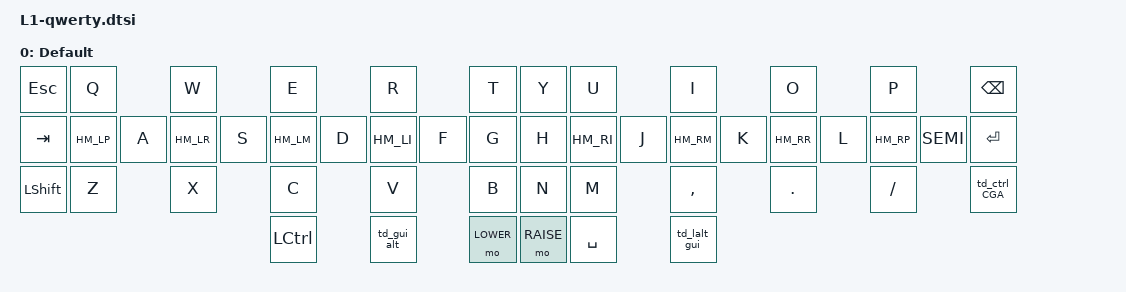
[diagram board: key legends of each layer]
/**
 *
 */

/ {
  keymap {
    compatible = "zmk,keymap";

	default_layer {
		label = "Default";
		bindings = <
// ╭───────────────┬───────────────┬───────────────┬───────────────┬───────────────┬───────────────╮   ╭───────────────┬───────────────┬───────────────┬───────────────┬───────────────┬───────────────╮
//  0               1               2               3               4               5                   6               7               8               9               10              11
    &kp ESC         &kp Q           &kp W           &kp E           &kp R           &kp T               &kp Y           &kp U           &kp I           &kp O           &kp P         	&kp BSPC
// ├───────────────├───────────────┼───────────────┼───────────────┼───────────────┼───────────────┤   ├───────────────├───────────────┼───────────────┼───────────────┼───────────────┼───────────────┤
//  12              13              14              15              16              17                  18              19              20              21              22              23
    &kp TAB			HM_LP A      	HM_LR S       	HM_LM D      	HM_LI F      	&kp G               &kp H           HM_RI J     	HM_RM K   		HM_RR L      	HM_RP SEMI		&kp ENTER
// ├───────────────├───────────────┼───────────────┼───────────────┼───────────────┼───────────────┤   ├───────────────├───────────────┼───────────────┼───────────────┼───────────────┼───────────────┤
//  24              25              26              27              28              29                  30              31              32              33              34              35
    &kp LSHFT 		&kp Z     		&kp X      		&kp C      		&kp V       	&kp B               &kp N           &kp M       	&kp COMMA  		&kp DOT   		&kp FSLH  		&td_ctrl_CGA
// ╰───────────────┴───────────────┴───────────────┼───────────────┼───────────────┼───────────────┤   ├───────────────├───────────────┼───────────────┼───────────────┴───────────────┴───────────────╯
//                                                  36              37              38                  39              40              41
                                                    &kp LCTRL       &td_gui_alt		&mo LOWER			&mo RAISE		&kp SPACE 		&td_lalt_gui
//                                                 ╰───────────────┴───────────────┴───────────────╯   ╰───────────────┴───────────────┴───────────────╯
			>;
		};
  };
};
